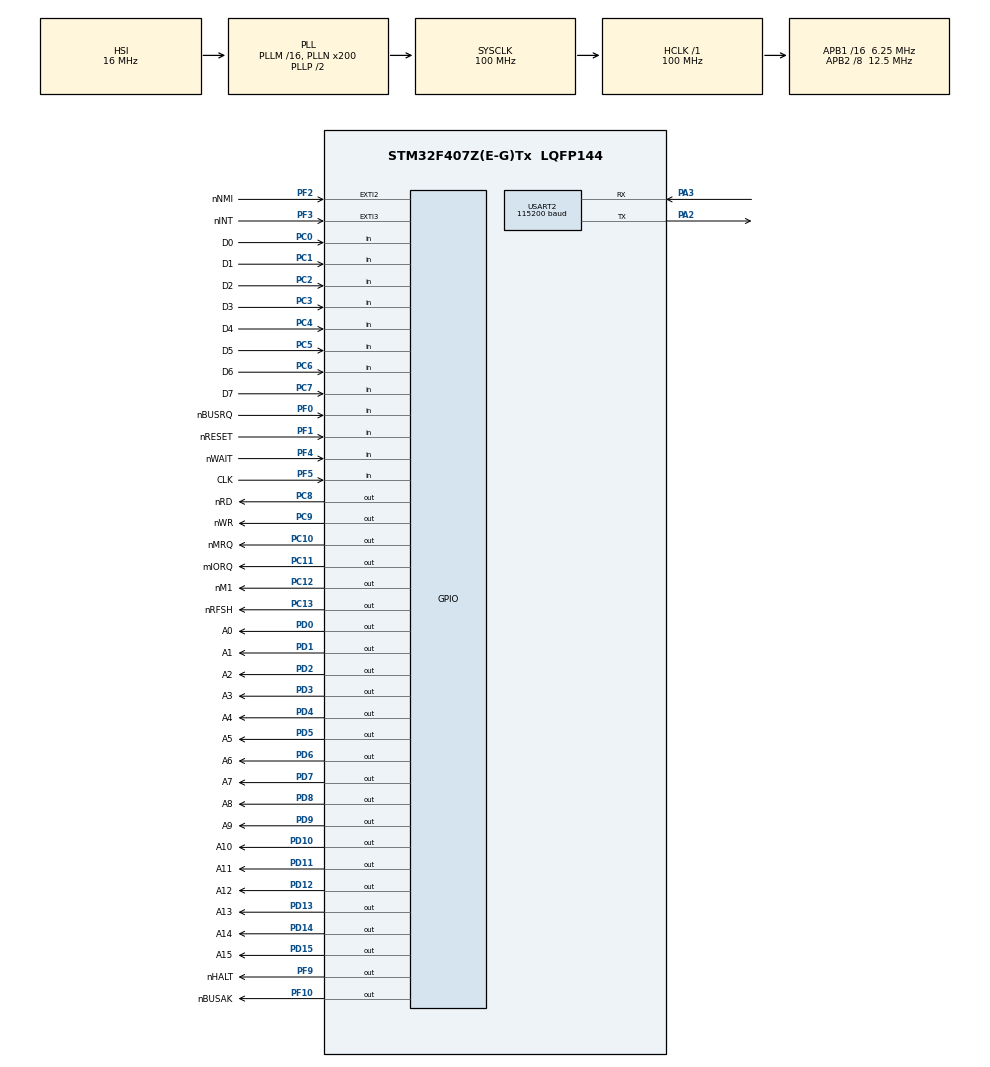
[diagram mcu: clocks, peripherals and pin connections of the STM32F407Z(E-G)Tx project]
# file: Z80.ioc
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Mcu.Family=STM32F4
Mcu.Name=STM32F407Z(E-G)Tx
Mcu.Package=LQFP144
NVIC.EXTI2_IRQn=true\:0\:0\:false\:false\:true\:true\:true
NVIC.EXTI3_IRQn=true\:0\:0\:false\:false\:true\:true\:true
NVIC.PriorityGroup=NVIC_PRIORITYGROUP_4
NVIC.USART2_IRQn=true\:0\:0\:false\:false\:true\:true\:true
PA2.Mode=Asynchronous
PA2.Signal=USART2_TX
PA3.Mode=Asynchronous
PA3.Signal=USART2_RX
PC0.GPIO_Label=D0
PC0.Signal=GPIO_Input
PC1.GPIO_Label=D1
PC1.Signal=GPIO_Input
PC10.GPIO_Label=nMRQ
PC10.PinState=GPIO_PIN_SET
PC10.Signal=GPIO_Output
PC11.GPIO_Label=mIORQ
PC11.PinState=GPIO_PIN_SET
PC11.Signal=GPIO_Output
PC12.GPIO_Label=nM1
PC12.PinState=GPIO_PIN_SET
PC12.Signal=GPIO_Output
PC13-ANTI_TAMP.GPIO_Label=nRFSH
PC13-ANTI_TAMP.PinState=GPIO_PIN_SET
PC13-ANTI_TAMP.Signal=GPIO_Output
PC2.GPIO_Label=D2
PC2.Signal=GPIO_Input
PC3.GPIO_Label=D3
PC3.Signal=GPIO_Input
PC4.GPIO_Label=D4
PC4.Signal=GPIO_Input
PC5.GPIO_Label=D5
PC5.Signal=GPIO_Input
PC6.GPIO_Label=D6
PC6.Signal=GPIO_Input
PC7.GPIO_Label=D7
PC7.Signal=GPIO_Input
PC8.GPIO_Label=nRD
PC8.PinState=GPIO_PIN_SET
PC8.Signal=GPIO_Output
PC9.GPIO_Label=nWR
PC9.PinState=GPIO_PIN_SET
PC9.Signal=GPIO_Output
PD0.GPIO_Label=A0
PD0.Signal=GPIO_Output
PD1.GPIO_Label=A1
PD1.Signal=GPIO_Output
PD10.GPIO_Label=A10
PD10.Signal=GPIO_Output
PD11.GPIO_Label=A11
PD11.Signal=GPIO_Output
PD12.GPIO_Label=A12
PD12.Signal=GPIO_Output
PD13.GPIO_Label=A13
PD13.Signal=GPIO_Output
PD14.GPIO_Label=A14
PD14.Signal=GPIO_Output
PD15.GPIO_Label=A15
PD15.Signal=GPIO_Output
PD2.GPIO_Label=A2
PD2.Signal=GPIO_Output
PD3.GPIO_Label=A3
PD3.Signal=GPIO_Output
PD4.GPIO_Label=A4
PD4.Signal=GPIO_Output
PD5.GPIO_Label=A5
PD5.Signal=GPIO_Output
PD6.GPIO_Label=A6
PD6.Signal=GPIO_Output
PD7.GPIO_Label=A7
PD7.Signal=GPIO_Output
PD8.GPIO_Label=A8
PD8.Signal=GPIO_Output
PD9.GPIO_Label=A9
PD9.Signal=GPIO_Output
PF0.GPIO_Label=nBUSRQ
PF0.GPIO_PuPd=GPIO_PULLUP
PF0.Signal=GPIO_Input
PF1.GPIO_Label=nRESET
PF1.GPIO_PuPd=GPIO_PULLUP
PF1.Signal=GPIO_Input
PF10.GPIO_Label=nBUSAK
PF10.GPIO_ModeDefaultOutputPP=GPIO_MODE_OUTPUT_PP
PF10.PinState=GPIO_PIN_SET
PF10.Signal=GPIO_Output
PF2.GPIO_Label=nNMI
PF2.GPIO_ModeDefaultEXTI=GPIO_MODE_IT_FALLING
PF2.GPIO_PuPd=GPIO_PULLUP
PF2.Signal=GPXTI2
PF3.GPIO_Label=nINT
PF3.GPIO_ModeDefaultEXTI=GPIO_MODE_IT_FALLING
PF3.GPIO_PuPd=GPIO_PULLUP
PF3.Signal=GPXTI3
PF4.GPIO_Label=nWAIT
PF4.GPIO_PuPd=GPIO_PULLUP
PF4.Signal=GPIO_Input
PF5.GPIO_Label=CLK
PF5.GPIO_PuPd=GPIO_PULLDOWN
PF5.Signal=GPIO_Input
PF9.GPIO_Label=nHALT
PF9.GPIO_ModeDefaultOutputPP=GPIO_MODE_OUTPUT_PP
PF9.PinState=GPIO_PIN_SET
PF9.Signal=GPIO_Output
ProjectManager.HeapSize=0x200
ProjectManager.StackSize=0x400
ProjectManager.TargetToolchain=STM32CubeIDE
RCC.48MHZClocksFreq_Value=50000000
RCC.AHBFreq_Value=100000000
RCC.APB1CLKDivider=RCC_HCLK_DIV16
RCC.APB1Freq_Value=6250000
RCC.APB1TimFreq_Value=12500000
RCC.APB2CLKDivider=RCC_HCLK_DIV8
RCC.APB2Freq_Value=12500000
RCC.APB2TimFreq_Value=25000000
RCC.CortexFreq_Value=100000000
RCC.HCLKFreq_Value=100000000
RCC.HSE_VALUE=25000000
RCC.HSI_VALUE=16000000
RCC.LSE_VALUE=32768
RCC.PLLN=200
RCC.SYSCLKFreq_VALUE=100000000
RCC.SYSCLKSource=RCC_SYSCLKSOURCE_PLLCLK
RCC.VCOOutputFreq_Value=200000000
USART2.BaudRate=115200
USART2.VirtualMode=VM_ASYNC
board=custom

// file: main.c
/* USER CODE BEGIN Header */
/**
  ******************************************************************************
  * @file           : main.c
  * @brief          : Main program body
  ******************************************************************************
  * @attention
  *
  * Copyright (c) 2022 STMicroelectronics.
  * All rights reserved.
  *
  * This software is licensed under terms that can be found in the LICENSE file
  * in the root directory of this software component.
  * If no LICENSE file comes with this software, it is provided AS-IS.
  *
  ******************************************************************************
  */
/* USER CODE END Header */
#include "main.h"

/* USER CODE BEGIN Includes */
#include "UserApp.h"
#include "retarget.h"
/* USER CODE END Includes */

UART_HandleTypeDef huart2;

void SystemClock_Config(void);
static void MX_GPIO_Init(void);
static void MX_USART2_UART_Init(void);

int main(void)
{

  /* MCU Configuration--------------------------------------------------------*/

  /* Reset of all peripherals, Initializes the Flash interface and the Systick. */
  HAL_Init();

  /* Configure the system clock */
  SystemClock_Config();

  /* Initialize all configured peripherals */
  MX_GPIO_Init();
  MX_USART2_UART_Init();
  /* USER CODE BEGIN 2 */
  setup();
  /* USER CODE END 2 */

  /* Infinite loop */
  while (1)
  {

    /* USER CODE BEGIN 3 */
	loop();
  }
  /* USER CODE END 3 */
}

void SystemClock_Config(void)
{
  RCC_OscInitTypeDef RCC_OscInitStruct = {0};
  RCC_ClkInitTypeDef RCC_ClkInitStruct = {0};

  /** Configure the main internal regulator output voltage
  */
  __HAL_RCC_PWR_CLK_ENABLE();
  __HAL_PWR_VOLTAGESCALING_CONFIG(PWR_REGULATOR_VOLTAGE_SCALE1);
  /** Initializes the RCC Oscillators according to the specified parameters
  * in the RCC_OscInitTypeDef structure.
  */
  RCC_OscInitStruct.OscillatorType = RCC_OSCILLATORTYPE_HSI;
  RCC_OscInitStruct.HSIState = RCC_HSI_ON;
  RCC_OscInitStruct.HSICalibrationValue = RCC_HSICALIBRATION_DEFAULT;
  RCC_OscInitStruct.PLL.PLLState = RCC_PLL_ON;
  RCC_OscInitStruct.PLL.PLLSource = RCC_PLLSOURCE_HSI;
  RCC_OscInitStruct.PLL.PLLM = 16;
  RCC_OscInitStruct.PLL.PLLN = 200;
  RCC_OscInitStruct.PLL.PLLP = RCC_PLLP_DIV2;
  RCC_OscInitStruct.PLL.PLLQ = 4;
  if (HAL_RCC_OscConfig(&RCC_OscInitStruct) != HAL_OK)
  {
    Error_Handler();
  }
  /** Initializes the CPU, AHB and APB buses clocks
  */
  RCC_ClkInitStruct.ClockType = RCC_CLOCKTYPE_HCLK|RCC_CLOCKTYPE_SYSCLK
                              |RCC_CLOCKTYPE_PCLK1|RCC_CLOCKTYPE_PCLK2;
  RCC_ClkInitStruct.SYSCLKSource = RCC_SYSCLKSOURCE_PLLCLK;
  RCC_ClkInitStruct.AHBCLKDivider = RCC_SYSCLK_DIV1;
  RCC_ClkInitStruct.APB1CLKDivider = RCC_HCLK_DIV16;
  RCC_ClkInitStruct.APB2CLKDivider = RCC_HCLK_DIV8;

  if (HAL_RCC_ClockConfig(&RCC_ClkInitStruct, FLASH_LATENCY_3) != HAL_OK)
  {
    Error_Handler();
  }
}

static void MX_USART2_UART_Init(void)
{

  huart2.Instance = USART2;
  huart2.Init.BaudRate = 115200;
  huart2.Init.WordLength = UART_WORDLENGTH_8B;
  huart2.Init.StopBits = UART_STOPBITS_1;
  huart2.Init.Parity = UART_PARITY_NONE;
  huart2.Init.Mode = UART_MODE_TX_RX;
  huart2.Init.HwFlowCtl = UART_HWCONTROL_NONE;
  huart2.Init.OverSampling = UART_OVERSAMPLING_16;
  if (HAL_UART_Init(&huart2) != HAL_OK)
  {
    Error_Handler();
  }
  /* USER CODE BEGIN USART2_Init 2 */
  RetargetInit(&huart2);
  /* USER CODE END USART2_Init 2 */

}

static void MX_GPIO_Init(void)
{
  GPIO_InitTypeDef GPIO_InitStruct = {0};

  /* GPIO Ports Clock Enable */
  __HAL_RCC_GPIOC_CLK_ENABLE();
  __HAL_RCC_GPIOF_CLK_ENABLE();
  __HAL_RCC_GPIOA_CLK_ENABLE();
  __HAL_RCC_GPIOD_CLK_ENABLE();

  /*Configure GPIO pin Output Level */
  HAL_GPIO_WritePin(GPIOC, nRFSH_Pin|nRD_Pin|nWR_Pin|nMRQ_Pin
                          |mIORQ_Pin|nM1_Pin, GPIO_PIN_SET);

  /*Configure GPIO pin Output Level */
  HAL_GPIO_WritePin(GPIOF, nHALT_Pin|nBUSAK_Pin, GPIO_PIN_SET);

  /*Configure GPIO pin Output Level */
  HAL_GPIO_WritePin(GPIOD, A8_Pin|A9_Pin|A10_Pin|A11_Pin
                          |A12_Pin|A13_Pin|A14_Pin|A15_Pin
                          |A0_Pin|A1_Pin|A2_Pin|A3_Pin
                          |A4_Pin|A5_Pin|A6_Pin|A7_Pin, GPIO_PIN_RESET);

  /*Configure GPIO pins : nRFSH_Pin nRD_Pin nWR_Pin nMRQ_Pin
                           mIORQ_Pin nM1_Pin */
  GPIO_InitStruct.Pin = nRFSH_Pin|nRD_Pin|nWR_Pin|nMRQ_Pin
                          |mIORQ_Pin|nM1_Pin;
  GPIO_InitStruct.Mode = GPIO_MODE_OUTPUT_PP;
  GPIO_InitStruct.Pull = GPIO_NOPULL;
  GPIO_InitStruct.Speed = GPIO_SPEED_FREQ_LOW;
  HAL_GPIO_Init(GPIOC, &GPIO_InitStruct);

  /*Configure GPIO pins : nBUSRQ_Pin nRESET_Pin nNMI_Pin nINT_Pin
                           nWAIT_Pin */
  GPIO_InitStruct.Pin = nBUSRQ_Pin|nRESET_Pin|nNMI_Pin|nINT_Pin
                          |nWAIT_Pin;
  GPIO_InitStruct.Mode = GPIO_MODE_INPUT;
  GPIO_InitStruct.Pull = GPIO_PULLUP;
  HAL_GPIO_Init(GPIOF, &GPIO_InitStruct);

  /*Configure GPIO pin : CLK_Pin */
  GPIO_InitStruct.Pin = CLK_Pin;
  GPIO_InitStruct.Mode = GPIO_MODE_INPUT;
  GPIO_InitStruct.Pull = GPIO_PULLDOWN;
  HAL_GPIO_Init(CLK_GPIO_Port, &GPIO_InitStruct);

  /*Configure GPIO pins : nHALT_Pin nBUSAK_Pin */
  GPIO_InitStruct.Pin = nHALT_Pin|nBUSAK_Pin;
  GPIO_InitStruct.Mode = GPIO_MODE_OUTPUT_PP;
  GPIO_InitStruct.Pull = GPIO_NOPULL;
  GPIO_InitStruct.Speed = GPIO_SPEED_FREQ_LOW;
  HAL_GPIO_Init(GPIOF, &GPIO_InitStruct);

  /*Configure GPIO pins : D0_Pin D1_Pin D2_Pin D3_Pin
                           D4_Pin D5_Pin D6_Pin D7_Pin */
  GPIO_InitStruct.Pin = D0_Pin|D1_Pin|D2_Pin|D3_Pin
                          |D4_Pin|D5_Pin|D6_Pin|D7_Pin;
  GPIO_InitStruct.Mode = GPIO_MODE_INPUT;
  GPIO_InitStruct.Pull = GPIO_NOPULL;
  HAL_GPIO_Init(GPIOC, &GPIO_InitStruct);

  /*Configure GPIO pins : A8_Pin A9_Pin A10_Pin A11_Pin
                           A12_Pin A13_Pin A14_Pin A15_Pin
                           A0_Pin A1_Pin A2_Pin A3_Pin
                           A4_Pin A5_Pin A6_Pin A7_Pin */
  GPIO_InitStruct.Pin = A8_Pin|A9_Pin|A10_Pin|A11_Pin
                          |A12_Pin|A13_Pin|A14_Pin|A15_Pin
                          |A0_Pin|A1_Pin|A2_Pin|A3_Pin
                          |A4_Pin|A5_Pin|A6_Pin|A7_Pin;
  GPIO_InitStruct.Mode = GPIO_MODE_OUTPUT_PP;
  GPIO_InitStruct.Pull = GPIO_NOPULL;
  GPIO_InitStruct.Speed = GPIO_SPEED_FREQ_LOW;
  HAL_GPIO_Init(GPIOD, &GPIO_InitStruct);

}

void Error_Handler(void)
{
  __disable_irq();
  while (1)
  {
  }
}
